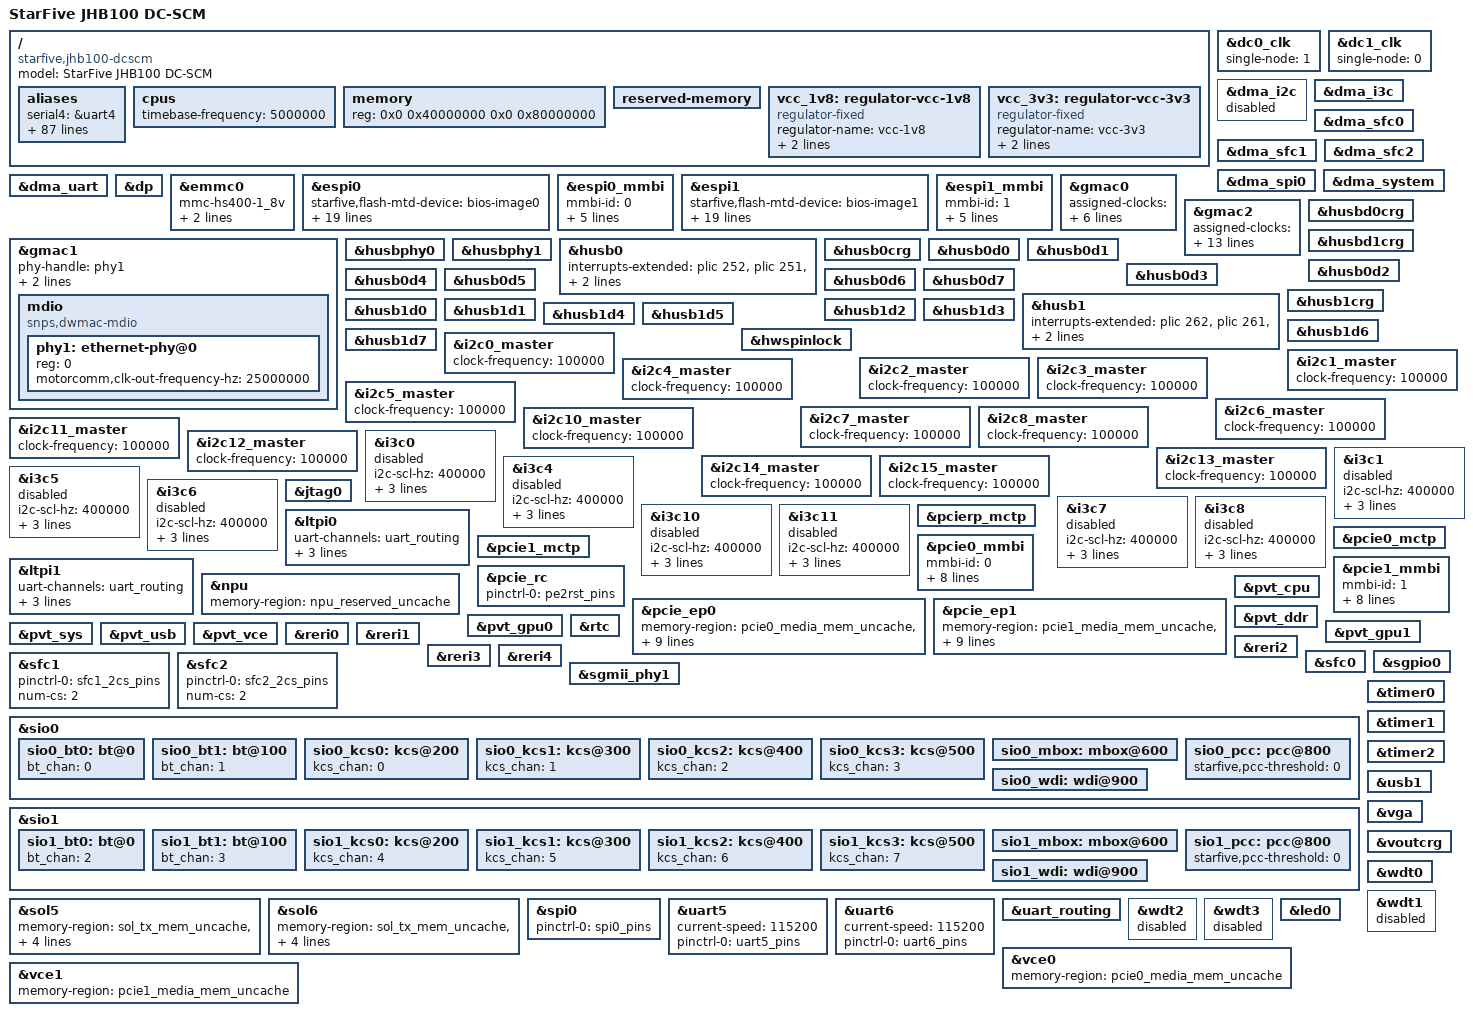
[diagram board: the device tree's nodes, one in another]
// SPDX-License-Identifier: GPL-2.0 OR MIT
/*
 * Copyright (c) 2026 StarFive Technology Co., Ltd.
 */

#include "jhb100.dtsi"
#include "jhb100-pinctrl.dtsi"
#include <dt-bindings/gpio/gpio.h>
#include <dt-bindings/i2c/i2c.h>

/ {
	model = "StarFive JHB100 DC-SCM";
	compatible = "starfive,jhb100-dcscm", "starfive,jhb100";

	aliases {
		serial4 = &uart4;
		serial5 = &uart5;
		serial6 = &uart6;
		serial7 = &uart7;
		serial8 = &uart8;
		serial9 = &uart9;
		serial10 = &uart10;
		serial11 = &uart11;
		serial12 = &uart12;
		serial13 = &uart13;
		serial14 = &uart14;

		ethernet0 = &gmac0;
		ethernet1 = &gmac1;
		ethernet2 = &gmac2;
		ethernet3 = &gmac3;

		i2c0 = &i2c0_master;
		i2c1 = &i2c0_slave;

		i2c2 = &i2c1_master;
		i2c3 = &i2c1_slave;

		i2c4 = &i2c2_master;
		i2c5 = &i2c2_slave;

		i2c6 = &i2c3_master;
		i2c7 = &i2c3_slave;

		i2c8 = &i2c4_master;
		i2c9 = &i2c4_slave;

		i2c10 = &i2c5_master;
		i2c11 = &i2c5_slave;

		i2c12 = &i2c6_master;
		i2c13 = &i2c6_slave;

		i2c14 = &i2c7_master;
		i2c15 = &i2c7_slave;

		i2c16 = &i2c8_master;
		i2c17 = &i2c8_slave;

		i2c18 = &i2c9_master;
		i2c19 = &i2c9_slave;

		i2c20 = &i2c10_master;
		i2c21 = &i2c10_slave;

		i2c22 = &i2c11_master;
		i2c23 = &i2c11_slave;

		i2c24 = &i2c12_master;
		i2c25 = &i2c12_slave;

		i2c26 = &i2c13_master;
		i2c27 = &i2c13_slave;

		i2c28 = &i2c14_master;
		i2c29 = &i2c14_slave;

		i2c30 = &i2c15_master;
		i2c31 = &i2c15_slave;

		i2c32 = &i3c0;
		i2c33 = &i3c1;
		i2c34 = &i3c2;
		i2c35 = &i3c3;
		i2c36 = &i3c4;
		i2c37 = &i3c5;
		i2c38 = &i3c6;
		i2c39 = &i3c7;
		i2c40 = &i3c8;
		i2c41 = &i3c9;
		i2c42 = &i3c10;
		i2c43 = &i3c11;
		i2c44 = &i3c12;
		i2c45 = &i3c13;
		i2c46 = &i3c14;
		i2c47 = &i3c15;

		i3c0 = &i3c0;
		i3c1 = &i3c1;
		i3c2 = &i3c2;
		i3c3 = &i3c3;
		i3c4 = &i3c4;
		i3c5 = &i3c5;
		i3c6 = &i3c6;
		i3c7 = &i3c7;
		i3c8 = &i3c8;
		i3c9 = &i3c9;
		i3c10 = &i3c10;
		i3c11 = &i3c11;
		i3c12 = &i3c12;
		i3c13 = &i3c13;
		i3c14 = &i3c14;
		i3c15 = &i3c15;

		mctp_pcie0 = &pcie0_mctp;
		mctp_pcie1 = &pcie1_mctp;
		mctp_pcie2 = &pcierp_mctp;

		peci0 = &peci0;
		peci4 = &peci1;

		spi0 = &sfc0;
		spi1 = &sfc1;
		spi2 = &sfc2;
		spi3 = &spi0;
	};

	cpus {
		timebase-frequency = <5000000>;
	};

	memory {
		device_type = "memory";
		reg = <0x0 0x40000000 0x0 0x80000000>;	/* 2GB */
	};

	reserved-memory {
		#address-cells = <0x2>;
		#size-cells = <0x2>;
		ranges;

		#include "jhb100-reserved-mem.dtsi"
		#include "jhb100-evb3-extend-reserved-mem.dtsi"
	};

	vcc_1v8: regulator-vcc-1v8 {
		compatible = "regulator-fixed";
		regulator-name = "vcc-1v8";
		regulator-min-microvolt = <1800000>;
		regulator-max-microvolt = <1800000>;
	};

	vcc_3v3: regulator-vcc-3v3 {
		compatible = "regulator-fixed";
		regulator-name = "vcc-3v3";
		regulator-min-microvolt = <3300000>;
		regulator-max-microvolt = <3300000>;
	};
};

&dc0_clk {
	single-node = <1>;
	status = "okay";
};

&dc1_clk {
	single-node = <0>;
	status = "okay";
};

&dma_i2c {
	status = "disabled";
};

&dma_i3c {
	status = "okay";
};

&dma_sfc0 {
	status = "okay";
};

&dma_sfc1 {
	status = "okay";
};

&dma_sfc2 {
	status = "okay";
};

&dma_spi0 {
	status = "okay";
};

&dma_system {
	status = "okay";
};

&dma_uart {
	status = "okay";
};

&dp {
	status = "okay";
};

&emmc0 {
	mmc-hs400-1_8v;
	max-frequency = <200000000>;
	non-removable;
	status = "okay";
};

&espi0 {
	starfive,flash-mtd-device = "bios-image0";
	starfive,host-src-addr = /bits/ 64 <0xf6810000>;
	perif-memcyc-size = <0x400000>;
	memory-region = <&espi0_mmbi_buffer_uncache>,
			<&espi0_perif_mem_uncache>,
			<&espi0_vw_mem_uncache>;

	starfive,bt-remap-num = <2>;
	starfive,kcs-remap-num = <4>;
	starfive,uart-remap-num = <2>;
	starfive,bt-io-addr = /bits/ 32 <0xe4 0xf4>;
	starfive,kcs-io-addr = /bits/ 32 <0xca2 0xcb2 0xcc2 0xcd2>;
	starfive,uart-io-addr = /bits/ 32 <0x3f8 0x410>;
	starfive,wdi-io-addr = /bits/ 32 <0xa00>;
	starfive,mbox-io-addr = /bits/ 32 <0x300>;

	starfive,vgpio_dir_bits = /bits/ 64 <0xffffffff00000000 0x0000000000000000>;
	starfive,vgpio_lvl_bits = /bits/ 64 <0x0000000000000000 0x0000000000000000>;
	starfive,vgpio_phy_bits = /bits/ 64 <0x0000000f0000000f 0x0000000000000000>;

	status = "okay";
};

&espi0_mmbi {
	mmbi-id = /bits/ 8 <0>;
	mmbi-instance-num = /bits/ 32 <1>;
	mmbi-instance-size = /bits/ 32 <0x10000>;
	mmbi-src-addr-offset = /bits/ 32 <0x10000>;
	mmbi-osuse = /bits/ 8 <0 0 0 0 0 0 0 0>;
	memory-region = <&espi0_mmbi_buffer_uncache>;
	status = "okay";
};

&espi1 {
	starfive,flash-mtd-device = "bios-image1";
	starfive,host-src-addr = /bits/ 64 <0xf6810000>;
	perif-memcyc-size = <0x400000>;
	memory-region = <&espi1_mmbi_buffer_uncache>,
			<&espi1_perif_mem_uncache>,
			<&espi1_vw_mem_uncache>;

	starfive,bt-remap-num = <2>;
	starfive,kcs-remap-num = <4>;
	starfive,uart-remap-num = <2>;
	starfive,bt-io-addr = /bits/ 32 <0xe4 0xf4>;
	starfive,kcs-io-addr = /bits/ 32 <0xca2 0xcb2 0xcc2 0xcd2>;
	starfive,uart-io-addr = /bits/ 32 <0x3f8 0x410>;
	starfive,wdi-io-addr = /bits/ 32 <0xa00>;
	starfive,mbox-io-addr = /bits/ 32 <0x300>;

	starfive,vgpio_dir_bits = /bits/ 64 <0xffffffff00000000 0x0000000000000000>;
	starfive,vgpio_lvl_bits = /bits/ 64 <0x0000000000000000 0x0000000000000000>;
	starfive,vgpio_phy_bits = /bits/ 64 <0x0000000f0000000f 0x0000000000000000>;

	status = "okay";
};

&espi1_mmbi {
	mmbi-id = /bits/ 8 <1>;
	mmbi-instance-num = /bits/ 32 <1>;
	mmbi-instance-size = /bits/ 32 <0x10000>;
	mmbi-src-addr-offset = /bits/ 32 <0x10000>;
	mmbi-osuse = /bits/ 8 <0 0 0 0 0 0 0 0>;
	memory-region = <&espi1_mmbi_buffer_uncache>;
	status = "okay";
};

&gmac0 {
	assigned-clocks = <&per3crg JHB100_PER3CLK_GMAC0_RMII_MUX>;
	assigned-clock-parents = <&per3_gmac0_rmii_rclki>;
	pinctrl-names = "default";
	mac-mode = "rmii";
	snps,use-ncsi;
	snps,ps-speed = <100>;
	pinctrl-0 = <&gmac0_rmii_pins>;
	status = "okay";
};

&gmac1 {
	phy-handle = <&phy1>;
	pinctrl-names = "default";
	pinctrl-0 = <&gmac1_mdio_pins>;
	snps,ps-speed = <1000>;
	status = "okay";

	mdio {
		#address-cells = <1>;
		#size-cells = <0>;
		compatible = "snps,dwmac-mdio";

		phy1: ethernet-phy@0 {
			reg = <0>;
			motorcomm,clk-out-frequency-hz = <25000000>;
		};
	};
};

&gmac2 {
	assigned-clocks = <&per2crg JHB100_PER2CLK_GMAC2_RMII_MUX_DLY>,
			  <&per2crg JHB100_PER2CLK_GMAC2_TX_MUX>,
			  <&per2crg JHB100_PER2CLK_GMAC2_RX_MUX_DLY>,
			  <&per2crg JHB100_PER2CLK_GMAC2_TXCK_MUX_DLY>;
	assigned-clock-parents = <&per2crg JHB100_PER2CLK_GMAC2_RMII_50>,
				 <&per2crg JHB100_PER2CLK_GMAC2_RMII_DIV>,
				 <&per2crg JHB100_PER2CLK_GMAC2_RMII_DIV>,
				 <&per2crg JHB100_PER2CLK_GMAC2_RMII_50>;
	pinctrl-names = "default";
	pinctrl-0 = <&gmac2_rmii_pins>;
	mac-mode = "rmii";
	snps,use-ncsi;
	snps,ps-speed = <100>;
	status = "okay";
};

&husbd0crg {
	status = "okay";
};

&husbd1crg {
	status = "okay";
};

&husbphy0 {
	status = "okay";
};

&husbphy1 {
	status = "okay";
};

&husb0 {
	interrupts-extended = <&plic 252>, <&plic 251>, <&plic 271>, <&intc 53>, <&intc 54>;
	interrupt-names = "host", "err", "pme", "perst_pe", "perst_ne";
	snps,export-xhci-to-pcie;
	status = "okay";
};

&husb0crg {
	status = "okay";
};

&husb0d0 {
	status = "okay";
};

&husb0d1 {
	status = "okay";
};

&husb0d2 {
	status = "okay";
};

&husb0d3 {
	status = "okay";
};

&husb0d4 {
	status = "okay";
};

&husb0d5 {
	status = "okay";
};

&husb0d6 {
	status = "okay";
};

&husb0d7 {
	status = "okay";
};

&husb1 {
	interrupts-extended = <&plic 262>, <&plic 261>, <&plic 315>, <&intc 55>, <&intc 56>;
	interrupt-names = "host", "err", "pme", "perst_pe", "perst_ne";
	snps,export-xhci-to-pcie;
	status = "okay";
};

&husb1crg {
	status = "okay";
};

&husb1d0 {
	status = "okay";
};

&husb1d1 {
	status = "okay";
};

&husb1d2 {
	status = "okay";
};

&husb1d3 {
	status = "okay";
};

&husb1d4 {
	status = "okay";
};

&husb1d5 {
	status = "okay";
};

&husb1d6 {
	status = "okay";
};

&husb1d7 {
	status = "okay";
};

&hwspinlock {
	status = "okay";
};

&i2c0_master {
	clock-frequency = <100000>;
	status = "okay";
};

&i2c1_master {
	clock-frequency = <100000>;
	status = "okay";
};

&i2c2_master {
	clock-frequency = <100000>;
	status = "okay";
};

&i2c3_master {
	clock-frequency = <100000>;
	status = "okay";
};

&i2c4_master {
	clock-frequency = <100000>;
	status = "okay";
};

&i2c5_master {
	clock-frequency = <100000>;
	status = "okay";
};

&i2c6_master {
	clock-frequency = <100000>;
	status = "okay";
};

&i2c7_master {
	clock-frequency = <100000>;
	status = "okay";
};

&i2c8_master {
	clock-frequency = <100000>;
	status = "okay";
};

&i2c10_master {
	clock-frequency = <100000>;
	status = "okay";
};

&i2c11_master {
	clock-frequency = <100000>;
	status = "okay";
};

&i2c12_master {
	clock-frequency = <100000>;
	status = "okay";
};

&i2c13_master {
	clock-frequency = <100000>;
	status = "okay";
};

&i2c14_master {
	clock-frequency = <100000>;
	status = "okay";
};

&i2c15_master {
	clock-frequency = <100000>;
	status = "okay";
};

&i3c0 {
	i2c-scl-hz = <400000>;
	i3c-scl-hz = <1000000>;
	mode = "master";
	hotjoin;
	status = "disabled";
};

&i3c1 {
	i2c-scl-hz = <400000>;
	i3c-scl-hz = <1000000>;
	mode = "master";
	hotjoin;
	status = "disabled";
};

&i3c4 {
	i2c-scl-hz = <400000>;
	i3c-scl-hz = <1000000>;
	mode = "master";
	hotjoin;
	status = "disabled";
};

&i3c5 {
	i2c-scl-hz = <400000>;
	i3c-scl-hz = <1000000>;
	mode = "master";
	hotjoin;
	status = "disabled";
};

&i3c6 {
	i2c-scl-hz = <400000>;
	i3c-scl-hz = <1000000>;
	mode = "master";
	hotjoin;
	status = "disabled";
};

&i3c7 {
	i2c-scl-hz = <400000>;
	i3c-scl-hz = <1000000>;
	mode = "master";
	hotjoin;
	status = "disabled";
};

&i3c8 {
	i2c-scl-hz = <400000>;
	i3c-scl-hz = <1000000>;
	mode = "master";
	hotjoin;
	status = "disabled";
};

&i3c10 {
	i2c-scl-hz = <400000>;
	i3c-scl-hz = <1000000>;
	mode = "master";
	hotjoin;
	status = "disabled";
};

&i3c11 {
	i2c-scl-hz = <400000>;
	i3c-scl-hz = <1000000>;
	mode = "master";
	hotjoin;
	status = "disabled";
};

&jtag0 {
	status = "okay";
};

&ltpi0 {
	uart-channels = <&uart_routing>;
	uart-max-baudrate = /bits/ 32 <115200>;
	data-sup;
	ddr-sup;
	status = "okay";
};

&ltpi1 {
	uart-channels = <&uart_routing>;
	uart-max-baudrate = /bits/ 32 <115200>;
	data-sup;
	ddr-sup;
	status = "okay";
};

&npu {
	memory-region = <&npu_reserved_uncache>;
	status = "okay";
};

&pcierp_mctp {
	status = "okay";
};

&pcie0_mctp {
	status = "okay";
};

&pcie0_mmbi {
	mmbi-id = /bits/ 8 <0>;
	mmbi-instance-num = /bits/ 32 <8>;
	mmbi-instance-size = /bits/ 32 <0x10000>;
	mmbi-src-addr-offset = /bits/ 32 <0>;
	mmbi-osuse = /bits/ 8 <1 1 1 1 1 1 1 1>;
	memory-region = <&pcie0_mmbi_buffer_uncache>;
	starfive,raise-irq-syscon = <&pcie_ep0_ecsr 0x700 0xd>;
	starfive,rst-en-syscon = <&strap_reg 0x50 0x400>;
	status = "okay";
};

&pcie1_mctp {
	status = "okay";
};

&pcie1_mmbi {
	mmbi-id = /bits/ 8 <1>;
	mmbi-instance-num = /bits/ 32 <8>;
	mmbi-instance-size = /bits/ 32 <0x10000>;
	mmbi-src-addr-offset = /bits/ 32 <0>;
	mmbi-osuse = /bits/ 8 <1 1 1 1 1 1 1 1>;
	memory-region = <&pcie1_mmbi_buffer_uncache>;
	starfive,raise-irq-syscon = <&pcie_ep1_ecsr 0x700 0xd>;
	starfive,rst-en-syscon = <&strap_reg 0x50 0x800>;
	status = "okay";
};

&pcie_rc {
	pinctrl-names = "default";
	pinctrl-0 = <&pe2rst_pins>;
	status = "okay";
};

&pcie_ep0 {
	memory-region = <&pcie0_media_mem_uncache>,
			<&pcie0_user_mem_uncache>,
			<&pcie0_mmbi_buffer_uncache>,
			<&pcie0_hdma_mem_uncache>;
	/*
	 * Resizable BAR default size = 2^(20+rebar-def-enc)MB.
	 * PF0 BAR2 = 16MB for HDMA data
	 * PF1 BAR4 = 64MB for VOUT frame buffer
	 * PF5 BAR0 = 32MB and BAR2 = 1MB are reserved for users
	 * PF6 BAR0 = 4MB for MMBI data
	 */
	rebar-def-enc-pf0-bar2 = <4>;
	rebar-def-enc-pf1-bar4 = <6>;
	rebar-def-enc-pf5-bar0 = <5>;
	rebar-def-enc-pf5-bar2 = <0>;
	rebar-def-enc-pf6-bar0 = <2>;
	starfive,support-usb-vout-func;
	status = "okay";
};

&pcie_ep1 {
	memory-region = <&pcie1_media_mem_uncache>,
			<&pcie1_user_mem_uncache>,
			<&pcie1_mmbi_buffer_uncache>,
			<&pcie1_hdma_mem_uncache>;
	/*
	 * Resizable BAR default size = 2^(20+rebar-def-enc)MB.
	 * PF0 BAR2 = 16MB for HDMA data
	 * PF1 BAR4 = 64MB for VOUT frame buffer
	 * PF5 BAR0 = 32MB and BAR2 = 1MB are reserved for users
	 * PF6 BAR0 = 4MB for MMBI data
	 */
	rebar-def-enc-pf0-bar2 = <4>;
	rebar-def-enc-pf1-bar4 = <6>;
	rebar-def-enc-pf5-bar0 = <5>;
	rebar-def-enc-pf5-bar2 = <0>;
	rebar-def-enc-pf6-bar0 = <2>;
	starfive,support-usb-vout-func;
	status = "okay";
};

&pvt_cpu {
	status = "okay";
};

&pvt_ddr {
	status = "okay";
};

&pvt_gpu0 {
	status = "okay";
};

&pvt_gpu1 {
	status = "okay";
};

&pvt_sys {
	status = "okay";
};

&pvt_usb {
	status = "okay";
};

&pvt_vce {
	status = "okay";
};

&reri0 {
	status = "okay";
};

&reri1 {
	status = "okay";
};

&reri2 {
	status = "okay";
};

&reri3 {
	status = "okay";
};

&reri4 {
	status = "okay";
};

&rtc {
	status = "okay";
};

&sfc0 {
	status = "okay";
};

&sfc1 {
	pinctrl-names = "default";
	pinctrl-0 = <&sfc1_2cs_pins>;
	num-cs = <2>;
	status = "okay";
};

&sfc2 {
	pinctrl-names = "default";
	pinctrl-0 = <&sfc2_2cs_pins>;
	num-cs = <2>;
	status = "okay";
};

&sgmii_phy1 {
	status = "okay";
};

&sgpio0 {
	status = "okay";
};

&sio0 {
	status = "okay";

	sio0_bt0: bt@0 {
		bt_chan = <0>;
		status = "okay";
	};

	sio0_bt1: bt@100 {
		bt_chan = <1>;
		status = "okay";
	};

	sio0_kcs0: kcs@200 {
		kcs_chan = <0>;
		status = "okay";
	};

	sio0_kcs1: kcs@300 {
		kcs_chan = <1>;
		status = "okay";
	};

	sio0_kcs2: kcs@400 {
		kcs_chan = <2>;
		status = "okay";
	};

	sio0_kcs3: kcs@500 {
		kcs_chan = <3>;
		status = "okay";
	};

	sio0_mbox: mbox@600 {
		status = "okay";
	};

	sio0_pcc: pcc@800 {
		starfive,pcc-threshold = <0>;
		status = "okay";
	};

	sio0_wdi: wdi@900 {
		status = "okay";
	};
};

&sio1 {
	status = "okay";

	sio1_bt0: bt@0 {
		bt_chan = <2>;
		status = "okay";
	};

	sio1_bt1: bt@100 {
		bt_chan = <3>;
		status = "okay";
	};

	sio1_kcs0: kcs@200 {
		kcs_chan = <4>;
		status = "okay";
	};

	sio1_kcs1: kcs@300 {
		kcs_chan = <5>;
		status = "okay";
	};

	sio1_kcs2: kcs@400 {
		kcs_chan = <6>;
		status = "okay";
	};

	sio1_kcs3: kcs@500 {
		kcs_chan = <7>;
		status = "okay";
	};

	sio1_mbox: mbox@600 {
		status = "okay";
	};

	sio1_pcc: pcc@800 {
		starfive,pcc-threshold = <0>;
		status = "okay";
	};

	sio1_wdi: wdi@900 {
		status = "okay";
	};
};

&sol5 {
	memory-region = <&sol_tx_mem_uncache>,
			<&sol_rx_mem_uncache>;
	tx-size = <3>;
	rx-size = <3>;
	dev-id = <5>;
	status = "okay";
};

&sol6 {
	memory-region = <&sol_tx_mem_uncache>,
			<&sol_rx_mem_uncache>;
	tx-size = <3>;
	rx-size = <3>;
	dev-id = <6>;
	status = "okay";
};

&spi0 {
	pinctrl-names = "default";
	pinctrl-0 = <&spi0_pins>;
	status = "okay";
};

&timer0 {
	status = "okay";
};

&timer1 {
	status = "okay";
};

&timer2 {
	status = "okay";
};

&uart5 {
	status = "okay";
	current-speed = <115200>;
	pinctrl-names = "default";
	pinctrl-0 = <&uart5_pins>;
};

&uart6 {
	status = "okay";
	current-speed = <115200>;
	pinctrl-names = "default";
	pinctrl-0 = <&uart6_pins>;
};

&uart_routing {
	status = "okay";
};

&usb1 {
	status = "okay";
};

&vga {
	status = "okay";
};

&voutcrg {
	status = "okay";
};

&wdt0 {
	status = "okay";
};

&wdt1 {
	status = "disabled";
};

&wdt2 {
	status = "disabled";
};

&wdt3 {
	status = "disabled";
};

&led0 {
	status = "okay";
};

&vce0 {
	memory-region = <&pcie0_media_mem_uncache>;
	status = "okay";
};

&vce1 {
	memory-region = <&pcie1_media_mem_uncache>;
	status = "okay";
};
